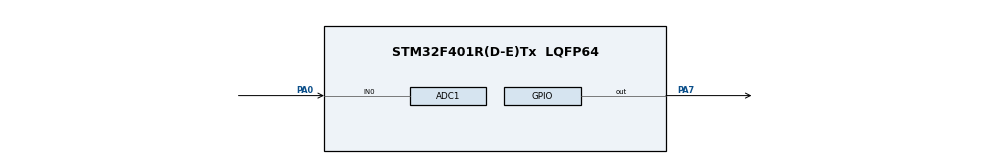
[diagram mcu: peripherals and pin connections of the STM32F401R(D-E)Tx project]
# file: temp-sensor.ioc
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ADC1.Channel-0\#ChannelRegularConversion=ADC_CHANNEL_0
ADC1.NbrOfConversionFlag=1
ADC1.Rank-0\#ChannelRegularConversion=1
ADC1.SamplingTime-0\#ChannelRegularConversion=ADC_SAMPLETIME_3CYCLES
ADC1.master=1
Mcu.Family=STM32F4
Mcu.Name=STM32F401R(D-E)Tx
Mcu.Package=LQFP64
NVIC.PriorityGroup=NVIC_PRIORITYGROUP_4
PA0-WKUP.Signal=ADCx_IN0
PA7.Signal=GPIO_Output
ProjectManager.HeapSize=0x200
ProjectManager.StackSize=0x400
ProjectManager.TargetToolchain=CMake
RCC.AHBFreq_Value=16000000
RCC.APB1Freq_Value=16000000
RCC.APB2Freq_Value=16000000
RCC.CortexFreq_Value=16000000
RCC.HSE_VALUE=25000000
RCC.HSI_VALUE=16000000
RCC.LSE_VALUE=32768
RCC.SYSCLKFreq_VALUE=16000000
RCC.VCOOutputFreq_Value=192000000
SH.ADCx_IN0.0=ADC1_IN0,IN0
board=custom

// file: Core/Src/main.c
#include "main.h"

ADC_HandleTypeDef hadc1;

uint32_t lightValue = 0;

void SystemClock_Config(void);
static void MX_GPIO_Init(void);
static void MX_ADC1_Init(void);

int main(void)
{
  HAL_Init();
  SystemClock_Config();
  MX_GPIO_Init();
  MX_ADC1_Init();

  /* USER CODE BEGIN 2 */
  // Initialization done by CubeMX
  /* USER CODE END 2 */

  /* Infinite loop */
  /* USER CODE BEGIN WHILE */
  while (1)
  {
    // 1. Read Light Sensor (PA0 configured as ADC1_IN0)
    HAL_ADC_Start(&hadc1);
    if (HAL_ADC_PollForConversion(&hadc1, 10) == HAL_OK)
    {
        lightValue = HAL_ADC_GetValue(&hadc1);
    }
    HAL_ADC_Stop(&hadc1);

    // 2. Threshold (Adjust this number 0-4095 based on your room light)
    uint32_t brightThreshold = 2500;

    // 3. Logic: Bright = Blink, Dark = Solid ON
    if (lightValue > brightThreshold)
    {
      // --- BRIGHT: BLINKING ---
      HAL_GPIO_WritePin(GPIOA, GPIO_PIN_7, GPIO_PIN_SET);
      HAL_Delay(200);
      HAL_GPIO_WritePin(GPIOA, GPIO_PIN_7, GPIO_PIN_RESET);
      HAL_Delay(200);
    }
    else
    {
      // --- DARK: CONSTANT YANMAK ---
      HAL_GPIO_WritePin(GPIOA, GPIO_PIN_7, GPIO_PIN_SET);
      HAL_Delay(50);
    }
    /* USER CODE END WHILE */
  }
}

static void MX_ADC1_Init(void)
{
  ADC_ChannelConfTypeDef sConfig = {0};
  hadc1.Instance = ADC1;
  hadc1.Init.Resolution = ADC_RESOLUTION_12B;
  hadc1.Init.ScanConvMode = DISABLE;
  hadc1.Init.ContinuousConvMode = DISABLE;
  HAL_ADC_Init(&hadc1);

  sConfig.Channel = ADC_CHANNEL_0; // PA0
  sConfig.Rank = 1;
  sConfig.SamplingTime = ADC_SAMPLETIME_3CYCLES;
  HAL_ADC_ConfigChannel(&hadc1, &sConfig);
}

static void MX_GPIO_Init(void)
{
  GPIO_InitTypeDef GPIO_InitStruct = {0};
  __HAL_RCC_GPIOA_CLK_ENABLE();

  HAL_GPIO_WritePin(GPIOA, GPIO_PIN_7, GPIO_PIN_RESET);

  GPIO_InitStruct.Pin = GPIO_PIN_7;
  GPIO_InitStruct.Mode = GPIO_MODE_OUTPUT_PP;
  GPIO_InitStruct.Pull = GPIO_NOPULL;
  GPIO_InitStruct.Speed = GPIO_SPEED_FREQ_LOW;
  HAL_GPIO_Init(GPIOA, &GPIO_InitStruct);
}

void SystemClock_Config(void)
{
  // Default system clock init...
}
